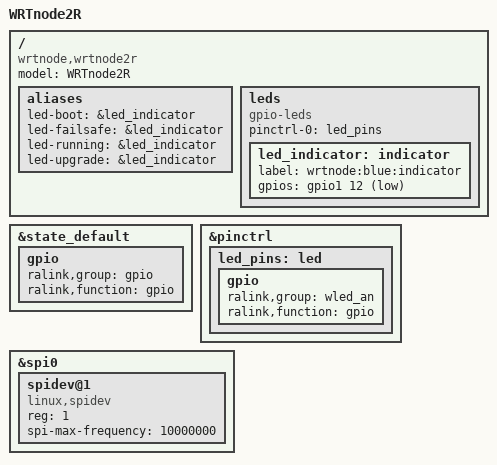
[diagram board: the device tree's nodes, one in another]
/dts-v1/;

#include "mt7628an_wrtnode_wrtnode2.dtsi"

/ {
	compatible = "wrtnode,wrtnode2r", "wrtnode,wrtnode2", "mediatek,mt7628an-soc";
	model = "WRTnode2R";

	aliases {
		led-boot = &led_indicator;
		led-failsafe = &led_indicator;
		led-running = &led_indicator;
		led-upgrade = &led_indicator;
	};

	leds {
		compatible = "gpio-leds";

		pinctrl-names = "default";
		pinctrl-0 = <&led_pins>;

		led_indicator: indicator {
			label = "wrtnode:blue:indicator";
			gpios = <&gpio1 12 GPIO_ACTIVE_LOW>;
		};
	};
};

&state_default {
	gpio {
		ralink,group = "gpio";
		ralink,function = "gpio";
	};
};

&pinctrl {
	led_pins: led {
		gpio {
			ralink,group = "wled_an";
			ralink,function = "gpio";
		};
	};
};

&spi0 {
	spidev@1 {
		#address-cells = <1>;
		#size-cells = <1>;
		compatible = "linux,spidev";
		reg = <1>;
		spi-max-frequency = <10000000>;
	};
};
